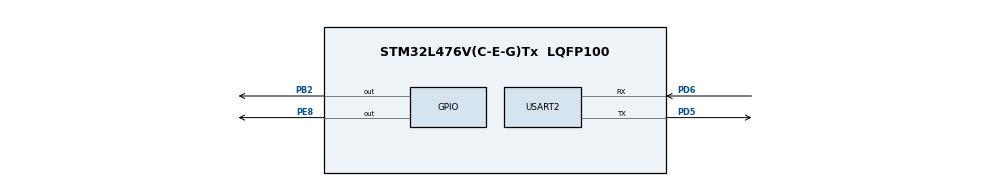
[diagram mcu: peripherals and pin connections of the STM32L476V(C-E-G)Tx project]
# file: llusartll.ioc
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Mcu.Family=STM32L4
Mcu.Name=STM32L476V(C-E-G)Tx
Mcu.Package=LQFP100
NVIC.PriorityGroup=NVIC_PRIORITYGROUP_4
PB2.Signal=GPIO_Output
PD5.Mode=Asynchronous
PD5.Signal=USART2_TX
PD6.Mode=Asynchronous
PD6.Signal=USART2_RX
PE8.Signal=GPIO_Output
ProjectManager.HeapSize=0x200
ProjectManager.StackSize=0x400
ProjectManager.TargetToolchain=EWARM V7
RCC.HSE_VALUE=8000000
RCC.HSI_VALUE=16000000
RCC.LSE_VALUE=32768
RCC.MSI_VALUE=4000000
RCC.VCOOutputFreq_Value=32000000
USART2.VirtualMode-Asynchronous=VM_ASYNC
board=custom

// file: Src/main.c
/* USER CODE BEGIN Header */
/**
  ******************************************************************************
  * @file           : main.c
  * @brief          : Main program body
  ******************************************************************************
  * @attention
  *
  * Copyright (c) 2025 STMicroelectronics.
  * All rights reserved.
  *
  * This software is licensed under terms that can be found in the LICENSE file
  * in the root directory of this software component.
  * If no LICENSE file comes with this software, it is provided AS-IS.
  *
  ******************************************************************************
  */
/* USER CODE END Header */
#include "main.h"

/* USER CODE BEGIN PV */
char rx_str[30], tx_str[30], tmp_str[10];
/* USER CODE END PV */

void SystemClock_Config(void);
static void MX_GPIO_Init(void);
static void MX_USART2_UART_Init(void);

/* USER CODE BEGIN 0 */
void USART_TX (uint8_t* dt, uint16_t sz)
{
  uint16_t ind = 0;
  while (ind<sz)
  {
    while (!LL_USART_IsActiveFlag_TXE(USART1)) {}
    LL_USART_TransmitData8(USART1,*(uint8_t*)(dt+ind));
    ind++;
  }
}
/* USER CODE END 0 */
uint16_t USART_RX_TX_Str (uint8_t* tx_dt, uint8_t* rx_dt)
{
  uint16_t ind = 0;
  while (!LL_USART_IsActiveFlag_RXNE(USART1)) {}
  rx_dt[ind] = (uint8_t)(USART1->DR & 0x00FF);
  while (!LL_USART_IsActiveFlag_TXE(USART1)) {}
  LL_USART_TransmitData8(USART1,*(uint8_t*)(tx_dt+ind));
  while(rx_dt[ind])
  {
    ind++;
    while (!LL_USART_IsActiveFlag_RXNE(USART1)) {}
    rx_dt[ind] = (uint8_t)(USART1->DR & 0x00FF);
    while (!LL_USART_IsActiveFlag_TXE(USART1)) {}
    LL_USART_TransmitData8(USART1,*(uint8_t*)(tx_dt+ind));
  }
  return ind;
}
int main(void)
{

  /* USER CODE BEGIN 1 */
  uint16_t i=0;
  /* USER CODE END 1 */

  /* MCU Configuration--------------------------------------------------------*/

  /* Reset of all peripherals, Initializes the Flash interface and the Systick. */
  LL_APB2_GRP1_EnableClock(LL_APB2_GRP1_PERIPH_SYSCFG);
  LL_APB1_GRP1_EnableClock(LL_APB1_GRP1_PERIPH_PWR);

  /* System interrupt init*/
  NVIC_SetPriorityGrouping(NVIC_PRIORITYGROUP_4);

  /* SysTick_IRQn interrupt configuration */
  NVIC_SetPriority(SysTick_IRQn, NVIC_EncodePriority(NVIC_GetPriorityGrouping(),15, 0));

  /* Configure the system clock */
  SystemClock_Config();

  /* Initialize all configured peripherals */
  MX_GPIO_Init();
  MX_USART2_UART_Init();
  /* USER CODE BEGIN 2 */
LL_mDelay(100);
  LL_GPIO_SetOutputPin(GPIOB, LL_GPIO_PIN_12);
  LL_SPI_Enable(SPI2);
  Init_7219();
  Number_7219(87654321);
  /* USER CODE END 2 */

  /* Infinite loop */
  while (1)
  {
sprintf(tx_str,"String  %04d\r\n",1023-i);
    USART_RX_TX_Str((uint8_t*)tx_str,(uint8_t*)rx_str);
    strncpy(tmp_str,rx_str+7,4);
    i = atoi (tmp_str);
    NumberR_7219(i);
    NumberL_7219(1023-i);
  }
}

void SystemClock_Config(void)
{
  LL_FLASH_SetLatency(LL_FLASH_LATENCY_0);
  while(LL_FLASH_GetLatency()!= LL_FLASH_LATENCY_0)
  {
  }
  LL_PWR_SetRegulVoltageScaling(LL_PWR_REGU_VOLTAGE_SCALE1);
  while (LL_PWR_IsActiveFlag_VOS() != 0)
  {
  }
  LL_RCC_MSI_Enable();

   /* Wait till MSI is ready */
  while(LL_RCC_MSI_IsReady() != 1)
  {

  }
  LL_RCC_MSI_EnableRangeSelection();
  LL_RCC_MSI_SetRange(LL_RCC_MSIRANGE_6);
  LL_RCC_MSI_SetCalibTrimming(0);
  LL_RCC_SetSysClkSource(LL_RCC_SYS_CLKSOURCE_MSI);

   /* Wait till System clock is ready */
  while(LL_RCC_GetSysClkSource() != LL_RCC_SYS_CLKSOURCE_STATUS_MSI)
  {

  }
  LL_RCC_SetAHBPrescaler(LL_RCC_SYSCLK_DIV_1);
  LL_RCC_SetAPB1Prescaler(LL_RCC_APB1_DIV_1);
  LL_RCC_SetAPB2Prescaler(LL_RCC_APB2_DIV_1);

  LL_Init1msTick(4000000);

  LL_SetSystemCoreClock(4000000);
}

static void MX_USART2_UART_Init(void)
{

  LL_USART_InitTypeDef USART_InitStruct = {0};

  LL_GPIO_InitTypeDef GPIO_InitStruct = {0};

  LL_RCC_SetUSARTClockSource(LL_RCC_USART2_CLKSOURCE_PCLK1);

  /* Peripheral clock enable */
  LL_APB1_GRP1_EnableClock(LL_APB1_GRP1_PERIPH_USART2);

  LL_AHB2_GRP1_EnableClock(LL_AHB2_GRP1_PERIPH_GPIOD);
  /**USART2 GPIO Configuration
  PD5   ------> USART2_TX
  PD6   ------> USART2_RX
  */
  GPIO_InitStruct.Pin = LL_GPIO_PIN_5|LL_GPIO_PIN_6;
  GPIO_InitStruct.Mode = LL_GPIO_MODE_ALTERNATE;
  GPIO_InitStruct.Speed = LL_GPIO_SPEED_FREQ_VERY_HIGH;
  GPIO_InitStruct.OutputType = LL_GPIO_OUTPUT_PUSHPULL;
  GPIO_InitStruct.Pull = LL_GPIO_PULL_NO;
  GPIO_InitStruct.Alternate = LL_GPIO_AF_7;
  LL_GPIO_Init(GPIOD, &GPIO_InitStruct);

  USART_InitStruct.BaudRate = 115200;
  USART_InitStruct.DataWidth = LL_USART_DATAWIDTH_8B;
  USART_InitStruct.StopBits = LL_USART_STOPBITS_1;
  USART_InitStruct.Parity = LL_USART_PARITY_NONE;
  USART_InitStruct.TransferDirection = LL_USART_DIRECTION_TX_RX;
  USART_InitStruct.HardwareFlowControl = LL_USART_HWCONTROL_NONE;
  USART_InitStruct.OverSampling = LL_USART_OVERSAMPLING_16;
  LL_USART_Init(USART2, &USART_InitStruct);
  LL_USART_ConfigAsyncMode(USART2);
  LL_USART_Enable(USART2);

}

static void MX_GPIO_Init(void)
{
  LL_GPIO_InitTypeDef GPIO_InitStruct = {0};

  /* GPIO Ports Clock Enable */
  LL_AHB2_GRP1_EnableClock(LL_AHB2_GRP1_PERIPH_GPIOB);
  LL_AHB2_GRP1_EnableClock(LL_AHB2_GRP1_PERIPH_GPIOE);
  LL_AHB2_GRP1_EnableClock(LL_AHB2_GRP1_PERIPH_GPIOD);

  /**/
  LL_GPIO_ResetOutputPin(GPIOB, LL_GPIO_PIN_2);

  /**/
  LL_GPIO_ResetOutputPin(GPIOE, LL_GPIO_PIN_8);

  /**/
  GPIO_InitStruct.Pin = LL_GPIO_PIN_2;
  GPIO_InitStruct.Mode = LL_GPIO_MODE_OUTPUT;
  GPIO_InitStruct.Speed = LL_GPIO_SPEED_FREQ_LOW;
  GPIO_InitStruct.OutputType = LL_GPIO_OUTPUT_PUSHPULL;
  GPIO_InitStruct.Pull = LL_GPIO_PULL_NO;
  LL_GPIO_Init(GPIOB, &GPIO_InitStruct);

  /**/
  GPIO_InitStruct.Pin = LL_GPIO_PIN_8;
  GPIO_InitStruct.Mode = LL_GPIO_MODE_OUTPUT;
  GPIO_InitStruct.Speed = LL_GPIO_SPEED_FREQ_LOW;
  GPIO_InitStruct.OutputType = LL_GPIO_OUTPUT_PUSHPULL;
  GPIO_InitStruct.Pull = LL_GPIO_PULL_NO;
  LL_GPIO_Init(GPIOE, &GPIO_InitStruct);

}

void Error_Handler(void)
{
  __disable_irq();
  while (1)
  {
  }
}
